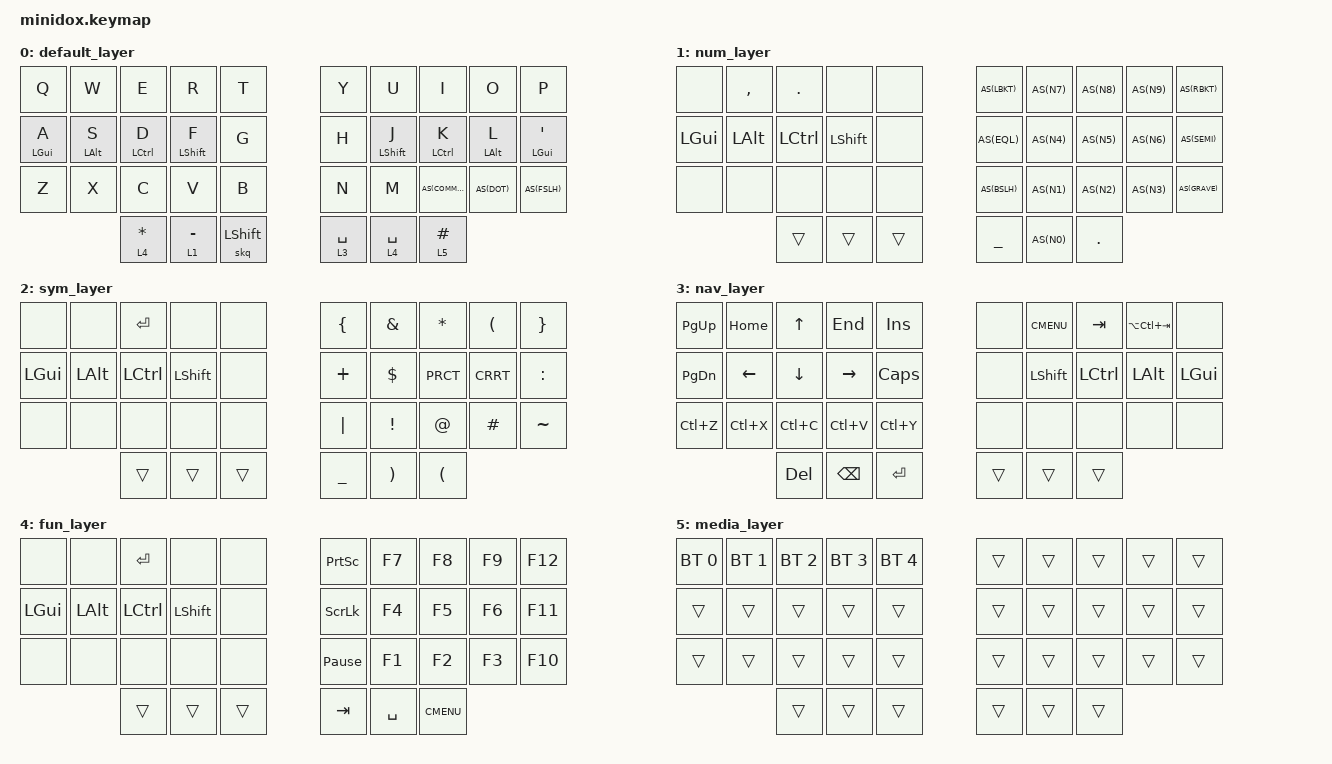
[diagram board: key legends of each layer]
#include <behaviors.dtsi>
#include <dt-bindings/zmk/keys.h>
#include <dt-bindings/zmk/bt.h>
#include <dt-bindings/zmk/outputs.h>


#define AS(keycode) &as LS(keycode) keycode

/ {
    behaviors {
      // auto shift behavior copied from: https://github.com/serebrov/zmk-config/blob/master/config/microdox.keymap#L23-L36
      as: auto_shift {
          compatible = "zmk,behavior-hold-tap";
          label = "AUTO_SHIFT";
          #binding-cells = <2>;
          tapping_term_ms = <200>;
          quick_tap_ms = <0>;
          flavor = "tap-preferred";
          bindings = <&kp>, <&kp>;
      };

      // Note: quick-release fixes the issue of sticky shift producing multiple upper case letters (see https://github.com/zmkfirmware/zmk/issues/903#issuecomment-909209198).
      skq: sticky_key_quick_release {
        compatible = "zmk,behavior-sticky-key";
        label = "STICKY_KEY_QUICK_RELEASE";
        #binding-cells = <1>;
        bindings = <&kp>;
        release-after-ms = <1000>;
        quick-release;
      };

      hm: homerow_mods {
          compatible = "zmk,behavior-hold-tap";
          label = "HOMEROW_MODS";
          #binding-cells = <2>;
          tapping-term-ms = <250>;
          quick-tap-ms = <0>;
          flavor = "tap-preferred";
          bindings = <&kp>, <&kp>;
      };
    };


    keymap {
      compatible = "zmk,keymap";

                default_layer {
// ----------------------------------------------------------------------------------------------------
// |  Q  |  W  |  E   |   R   |  T     |    |  Y    |  U   |  I    |  O   |   P   |
// |  A  |  S  |  D   |   F   |  G     |    |  H    |  J   |  K    |  L   |   '   |
// |  Z  |  X  |  C   |   V   |  B     |    |  N    |  M   |  ,    |  .   |   /   |
//               | *   |  -   | sticky-|    | SPC   | SPC | #     |
//         hold: | FUN | NUM  | -shift |    | NAV   | NAV | MEDIA |
                      bindings = <
  &kp Q      &kp W       &kp E       &kp R         &kp T        &kp Y        &kp U         &kp I        &kp O       &kp P
  &hm LGUI A &hm LALT S  &hm LCTRL D &hm LSHIFT F  &kp G        &kp H        &hm LSHIFT J  &hm LCTRL K  &hm LALT L  &hm LGUI SQT
  &kp Z      &kp X       &kp C       &kp V         &kp B        &kp N        &kp M         AS(COMMA)    AS(DOT)     AS(FSLH)
                      &lt 4 ASTRK  &lt 1 MINUS  &skq LSHFT    &lt 3 SPACE  &lt 4 SPACE  &lt 5 HASH
                        >;
                };


                num_layer {
      bindings = <
  &none     &kp COMMA  &kp DOT    &none       &none      AS(LBKT)   AS(N7)  AS(N8)  AS(N9)  AS(RBKT)
  &kp LGUI  &kp LALT   &kp LCTRL  &kp LSHFT   &none      AS(EQL)    AS(N4)  AS(N5)  AS(N6)  AS(SEMI)
  &none     &none      &none      &none       &none      AS(BSLH)   AS(N1)  AS(N2)  AS(N3)  AS(GRAVE)
                       &trans     &trans      &trans     &kp UNDER  AS(N0)  &kp DOT
                        >;
                };


                sym_layer {
      bindings = <
&none     &none      &kp RET    &none       &none      &kp LBRC   &kp AMPS  &kp ASTRK  &kp LPAR  &kp RBRC
&kp LGUI  &kp LALT   &kp LCTRL  &kp LSHFT   &none      &kp PLUS   &kp DLLR  &kp PRCT   &kp CRRT  &kp COLON
&none     &none      &none      &none       &none      &kp PIPE   &kp EXCL  &kp AT     &kp HASH  &kp TILDE
                     &trans     &trans      &trans     &kp UNDER  &kp RPAR  &kp LPAR
                        >;
                };


                nav_layer {
      bindings = <
&kp PG_UP   &kp HOME    &kp UP      &kp END     &kp INSERT       &none  &kp K_CMENU  &kp TAB    &kp LA(LC(TAB))  &none
&kp PG_DN   &kp LEFT    &kp DOWN    &kp RIGHT   &kp CAPSLOCK     &none  &kp LSHFT    &kp LCTRL  &kp LALT         &kp LGUI
&kp LC(Z)   &kp LC(X)   &kp LC(C)   &kp LC(V)   &kp LC(Y)        &none  &none        &none      &none            &none
                        &kp DEL     &kp BSPC    &kp RET          &trans &trans       &trans
                        >;
                };


                fun_layer {
      bindings = <
&none     &none      &kp RET    &none       &none      &kp PSCRN        &kp F7   &kp F8  &kp F9  &kp F12
&kp LGUI  &kp LALT   &kp LCTRL  &kp LSHFT   &none      &kp SLCK         &kp F4   &kp F5  &kp F6  &kp F11
&none     &none      &none      &none       &none      &kp PAUSE_BREAK  &kp F1   &kp F2  &kp F3  &kp F10
                     &trans     &trans      &trans     &kp TAB          &kp SPC  &kp K_CMENU
                        >;
                };




                media_layer {
// ------------------------------------------------------------------------------------------------------------
// | BTCLR | BT1 | BT2 |  BT3 |  BT4 |  BT5    |   |      |       |       |        |          |       |
// |OUT_TOG|     |     |      |      |         |   |      |       |       |        |          |       |
// |       |     |     |      |      |         |   |      |       |       |        |          |       |
//                     |      |      |         |   |      |       |       |
      bindings = <
&bt BT_SEL 0   &bt BT_SEL 1      &bt BT_SEL 2  &bt BT_SEL 3 &bt BT_SEL 4    &trans   &trans   &trans   &trans   &trans
&trans         &trans            &trans        &trans       &trans          &trans   &trans   &trans   &trans   &trans
&trans         &trans            &trans        &trans       &trans          &trans   &trans   &trans   &trans   &trans
                                 &trans        &trans       &trans          &trans   &trans   &trans
                        >;
                };

        };
};
